# TESTDEV register map
File version: 1.0
Fixture
Registers are 32-bit, read-write, reset 0x0 unless marked. A register's access mark holds for its fields unless they carry their own. Offsets are from the block's base; lines under a group give offsets from that group; [hi:lo] are bit positions; {n}, {i} and the like mark numbered series; 'fields as' and 'values as' point back to an identical list; <NAME> marks a mode.

## Memory map
0x40010800 GPIOA — GPIO
0x40010C00 GPIOB — B

## GPIOA — GPIO
Base 0x40010800
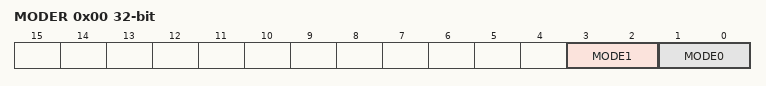
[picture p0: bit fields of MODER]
0x00 MODER — mode
  [3:2] MODE1 — m1
  [1:0] MODE0 — m0

## GPIOB — B
Base 0x40010C00
0x00 MODER — mode
  [1:0] MODE0 — m0
